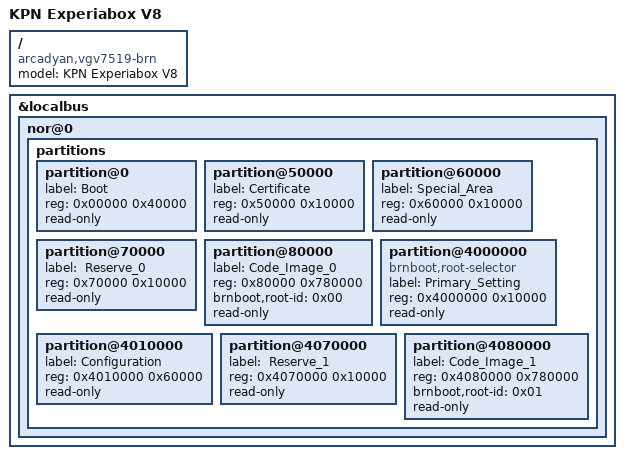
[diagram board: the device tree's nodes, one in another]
/dts-v1/;

#include "VGV7519.dtsi"

/ {
	compatible = "arcadyan,vgv7519-brn", "arcadyan,vgv7519", "lantiq,xway", "lantiq,vr9";
	model = "KPN Experiabox V8";
};

&localbus {
	nor@0 {
		partitions {
			partition@0 {
				label = "Boot";
				reg = <0x00000 0x40000>;
				read-only;
			};

			partition@50000 {
				label = "Certificate";
				reg = <0x50000 0x10000>;
				read-only;
			};
			partition@60000 {
				label = "Special_Area";
				reg = <0x60000 0x10000>;
				read-only;
			};

			partition@70000 {
				label = " Reserve_0";
				reg = <0x70000 0x10000>;
				read-only;
			};

			partition@80000 {
				label = "Code_Image_0";
				reg = <0x80000 0x780000>;
				brnboot,root-id = <0x00>;
				read-only;
			};

			partition@4000000 {
				compatible = "brnboot,root-selector";
				label = "Primary_Setting";
				reg = <0x4000000 0x10000>;
				read-only;
			};

			partition@4010000 {
				label = "Configuration";
				reg = <0x4010000 0x60000>;
				read-only;
			};

			partition@4070000 {
				label = " Reserve_1";
				reg = <0x4070000 0x10000>;
				read-only;
			};

			partition@4080000 {
				label = "Code_Image_1";
				reg = <0x4080000 0x780000>;
				brnboot,root-id = <0x01>;
				read-only;
			};
		};
	};
};
